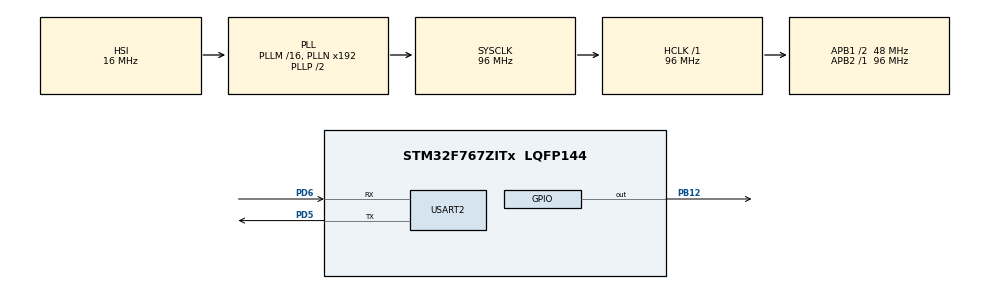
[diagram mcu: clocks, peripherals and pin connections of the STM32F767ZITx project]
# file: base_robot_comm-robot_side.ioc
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CORTEX_M7.default_mode_Activation=1
Mcu.Family=STM32F7
Mcu.Name=STM32F767ZITx
Mcu.Package=LQFP144
NVIC.PriorityGroup=NVIC_PRIORITYGROUP_4
NVIC.USART2_IRQn=true\:0\:0\:false\:false\:true\:true\:true\:true
PB12.Signal=GPIO_Output
PD5.Mode=Asynchronous
PD5.Signal=USART2_TX
PD6.Mode=Asynchronous
PD6.Signal=USART2_RX
ProjectManager.HeapSize=0x200
ProjectManager.StackSize=0x400
ProjectManager.TargetToolchain=STM32CubeIDE
RCC.AHBFreq_Value=96000000
RCC.APB1CLKDivider=RCC_HCLK_DIV2
RCC.APB1Freq_Value=48000000
RCC.APB1TimFreq_Value=96000000
RCC.APB2Freq_Value=96000000
RCC.APB2TimFreq_Value=96000000
RCC.CortexFreq_Value=96000000
RCC.HCLKFreq_Value=96000000
RCC.HSE_VALUE=25000000
RCC.HSI_VALUE=16000000
RCC.LSE_VALUE=32768
RCC.SYSCLKFreq_VALUE=96000000
RCC.SYSCLKSource=RCC_SYSCLKSOURCE_PLLCLK
RCC.USBFreq_Value=96000000
RCC.VCOOutputFreq_Value=192000000
USART2.VirtualMode-Asynchronous=VM_ASYNC
board=custom

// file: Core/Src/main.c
/* USER CODE BEGIN Header */
/**
  ******************************************************************************
  * @file           : main.c
  * @brief          : Main program body
  ******************************************************************************
  * @attention
  *
  * Copyright (c) 2025 STMicroelectronics.
  * All rights reserved.
  *
  * This software is licensed under terms that can be found in the LICENSE file
  * in the root directory of this software component.
  * If no LICENSE file comes with this software, it is provided AS-IS.
  *
  ******************************************************************************
  */
/* USER CODE END Header */
#include "main.h"

/* USER CODE BEGIN Includes */
#include "string.h"
/* USER CODE END Includes */

/* USER CODE BEGIN PD */
#define BUFFER_SIZE 8
#define BASE_STATE_BUSY 0
#define BASE_STATE_READY 1
/* USER CODE END PD */

UART_HandleTypeDef huart2;

/* USER CODE BEGIN PV */
uint8_t base_rx_buffer [BUFFER_SIZE] = {0};  // RX Buffer (for communication with Base)
uint8_t base_tx_buffer [BUFFER_SIZE] = {0};  // TX Buffer (for communication with Base)
volatile uint8_t base_state = BASE_STATE_BUSY;  // State of the base (initialize to busy)
uint8_t test1 [6] = {'0', '0', 'b', 'r', 'd', 'y'};
uint8_t test2 [6] = {'d', 'e', 'e', 'z', 'n', 't'};
/* USER CODE END PV */

void SystemClock_Config(void);
static void MPU_Config(void);
static void MX_GPIO_Init(void);
static void MX_USART2_UART_Init(void);
/* USER CODE BEGIN PFP */
void Send_to_Base (uint8_t addr, uint8_t *data, uint8_t is_ready);
void Receive_from_Base(void);
void Interpret_Commands(uint8_t *rx_buffer);
/* USER CODE END PFP */

/* USER CODE BEGIN 0 */

// Interpret commands
void Interpret_Commands(uint8_t *rx_buffer) {
	if (strstr((const char * ) rx_buffer, "jrdy")) {
		Send_to_Base('0', test1, 1);
	}
	if (strstr((const char * ) rx_buffer, "poll")) {
		Send_to_Base('0', test2, 1);
	}
}

// Function to send bytes to Base
void Send_to_Base (uint8_t addr, uint8_t *data, uint8_t is_ready) {
	while (base_state != BASE_STATE_READY) {}
	// Assign address
	base_tx_buffer[0] = addr;
	// Assign data (until before the last byte)
	for (int i = 1; i < BUFFER_SIZE - 1; i++) {
		base_tx_buffer[i] = data[i - 1];
	}
	// Assign status byte
	if (is_ready) {
		base_tx_buffer[BUFFER_SIZE - 1] = 'r';
	}
	else {
		base_tx_buffer[BUFFER_SIZE - 1] = 'n';
	}
	// Transmit data packet
	HAL_UART_Transmit_IT(&huart2, base_tx_buffer, BUFFER_SIZE);
}

// Function to Receive bytes from Base
void Receive_from_Base(void) {
	HAL_UART_Receive_IT(&huart2, base_rx_buffer, BUFFER_SIZE);
}

// Callback function after transmitting data
void HAL_UART_TxCpltCallback(UART_HandleTypeDef *huart) {
	if (huart->Instance == huart2.Instance) {
		// Transmission fully complete, now wait until robot sends data
		base_state = BASE_STATE_BUSY;
		Receive_from_Base();
	}
}

// Callback function after receiving data
void HAL_UART_RxCpltCallback(UART_HandleTypeDef *huart) {
	if (huart->Instance == huart2.Instance) {
		// Ready?
		if (base_rx_buffer[BUFFER_SIZE - 1] == 'r') {
			base_state = BASE_STATE_READY;
		}
		// Is this for Robot?
		if (base_rx_buffer[0] == '2') {
			// Interpret commands
			Interpret_Commands(base_rx_buffer);
		}
	}
}

/* USER CODE END 0 */

int main(void)
{

  /* MPU Configuration--------------------------------------------------------*/
  MPU_Config();

  /* MCU Configuration--------------------------------------------------------*/

  /* Reset of all peripherals, Initializes the Flash interface and the Systick. */
  HAL_Init();

  /* Configure the system clock */
  SystemClock_Config();

  /* Initialize all configured peripherals */
  MX_GPIO_Init();
  MX_USART2_UART_Init();
  /* USER CODE BEGIN 2 */
  Receive_from_Base();  // Start receiving from base
  /* USER CODE END 2 */

  /* Infinite loop */
  while (1)
  {

    /* USER CODE BEGIN 3 */
	  HAL_GPIO_TogglePin(GPIOB, GPIO_PIN_12);
	  HAL_Delay(1000);
  }
  /* USER CODE END 3 */
}

void SystemClock_Config(void)
{
  RCC_OscInitTypeDef RCC_OscInitStruct = {0};
  RCC_ClkInitTypeDef RCC_ClkInitStruct = {0};

  /** Configure the main internal regulator output voltage
  */
  __HAL_RCC_PWR_CLK_ENABLE();
  __HAL_PWR_VOLTAGESCALING_CONFIG(PWR_REGULATOR_VOLTAGE_SCALE3);

  /** Initializes the RCC Oscillators according to the specified parameters
  * in the RCC_OscInitTypeDef structure.
  */
  RCC_OscInitStruct.OscillatorType = RCC_OSCILLATORTYPE_HSI;
  RCC_OscInitStruct.HSIState = RCC_HSI_ON;
  RCC_OscInitStruct.HSICalibrationValue = RCC_HSICALIBRATION_DEFAULT;
  RCC_OscInitStruct.PLL.PLLState = RCC_PLL_ON;
  RCC_OscInitStruct.PLL.PLLSource = RCC_PLLSOURCE_HSI;
  RCC_OscInitStruct.PLL.PLLM = 16;
  RCC_OscInitStruct.PLL.PLLN = 192;
  RCC_OscInitStruct.PLL.PLLP = RCC_PLLP_DIV2;
  RCC_OscInitStruct.PLL.PLLQ = 2;
  RCC_OscInitStruct.PLL.PLLR = 2;
  if (HAL_RCC_OscConfig(&RCC_OscInitStruct) != HAL_OK)
  {
    Error_Handler();
  }

  /** Activate the Over-Drive mode
  */
  if (HAL_PWREx_EnableOverDrive() != HAL_OK)
  {
    Error_Handler();
  }

  /** Initializes the CPU, AHB and APB buses clocks
  */
  RCC_ClkInitStruct.ClockType = RCC_CLOCKTYPE_HCLK|RCC_CLOCKTYPE_SYSCLK
                              |RCC_CLOCKTYPE_PCLK1|RCC_CLOCKTYPE_PCLK2;
  RCC_ClkInitStruct.SYSCLKSource = RCC_SYSCLKSOURCE_PLLCLK;
  RCC_ClkInitStruct.AHBCLKDivider = RCC_SYSCLK_DIV1;
  RCC_ClkInitStruct.APB1CLKDivider = RCC_HCLK_DIV2;
  RCC_ClkInitStruct.APB2CLKDivider = RCC_HCLK_DIV1;

  if (HAL_RCC_ClockConfig(&RCC_ClkInitStruct, FLASH_LATENCY_3) != HAL_OK)
  {
    Error_Handler();
  }
}

static void MX_USART2_UART_Init(void)
{

  huart2.Instance = USART2;
  huart2.Init.BaudRate = 115200;
  huart2.Init.WordLength = UART_WORDLENGTH_8B;
  huart2.Init.StopBits = UART_STOPBITS_1;
  huart2.Init.Parity = UART_PARITY_NONE;
  huart2.Init.Mode = UART_MODE_TX_RX;
  huart2.Init.HwFlowCtl = UART_HWCONTROL_NONE;
  huart2.Init.OverSampling = UART_OVERSAMPLING_16;
  huart2.Init.OneBitSampling = UART_ONE_BIT_SAMPLE_DISABLE;
  huart2.AdvancedInit.AdvFeatureInit = UART_ADVFEATURE_NO_INIT;
  if (HAL_UART_Init(&huart2) != HAL_OK)
  {
    Error_Handler();
  }

}

static void MX_GPIO_Init(void)
{
  GPIO_InitTypeDef GPIO_InitStruct = {0};

  /* GPIO Ports Clock Enable */
  __HAL_RCC_GPIOB_CLK_ENABLE();
  __HAL_RCC_GPIOD_CLK_ENABLE();

  /*Configure GPIO pin Output Level */
  HAL_GPIO_WritePin(GPIOB, GPIO_PIN_12, GPIO_PIN_RESET);

  /*Configure GPIO pin : PB12 */
  GPIO_InitStruct.Pin = GPIO_PIN_12;
  GPIO_InitStruct.Mode = GPIO_MODE_OUTPUT_PP;
  GPIO_InitStruct.Pull = GPIO_NOPULL;
  GPIO_InitStruct.Speed = GPIO_SPEED_FREQ_LOW;
  HAL_GPIO_Init(GPIOB, &GPIO_InitStruct);

}

 /* MPU Configuration */

void MPU_Config(void)
{
  MPU_Region_InitTypeDef MPU_InitStruct = {0};

  /* Disables the MPU */
  HAL_MPU_Disable();

  /** Initializes and configures the Region and the memory to be protected
  */
  MPU_InitStruct.Enable = MPU_REGION_ENABLE;
  MPU_InitStruct.Number = MPU_REGION_NUMBER0;
  MPU_InitStruct.BaseAddress = 0x0;
  MPU_InitStruct.Size = MPU_REGION_SIZE_4GB;
  MPU_InitStruct.SubRegionDisable = 0x87;
  MPU_InitStruct.TypeExtField = MPU_TEX_LEVEL0;
  MPU_InitStruct.AccessPermission = MPU_REGION_NO_ACCESS;
  MPU_InitStruct.DisableExec = MPU_INSTRUCTION_ACCESS_DISABLE;
  MPU_InitStruct.IsShareable = MPU_ACCESS_SHAREABLE;
  MPU_InitStruct.IsCacheable = MPU_ACCESS_NOT_CACHEABLE;
  MPU_InitStruct.IsBufferable = MPU_ACCESS_NOT_BUFFERABLE;

  HAL_MPU_ConfigRegion(&MPU_InitStruct);
  /* Enables the MPU */
  HAL_MPU_Enable(MPU_PRIVILEGED_DEFAULT);

}

void Error_Handler(void)
{
  __disable_irq();
  while (1)
  {
  }
}
